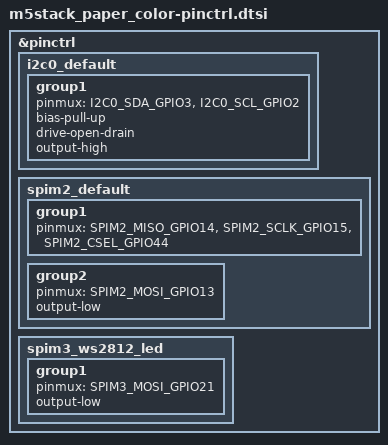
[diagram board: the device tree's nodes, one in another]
/*
 * Copyright (c) 2026 The Zephyr Project Contributors
 * SPDX-License-Identifier: Apache-2.0
 */

#include <zephyr/dt-bindings/pinctrl/esp32s3-pinctrl.h>

&pinctrl {
	i2c0_default: i2c0_default {
		group1 {
			pinmux = <I2C0_SDA_GPIO3>,
				 <I2C0_SCL_GPIO2>;
			bias-pull-up;
			drive-open-drain;
			output-high;
		};
	};

	spim2_default: spim2_default {
		group1 {
			pinmux = <SPIM2_MISO_GPIO14>,
				 <SPIM2_SCLK_GPIO15>,
				 <SPIM2_CSEL_GPIO44>;
		};

		group2 {
			pinmux = <SPIM2_MOSI_GPIO13>;
			output-low;
		};
	};

	spim3_ws2812_led: spim3_ws2812_led {
		group1 {
			pinmux = <SPIM3_MOSI_GPIO21>;
			output-low;
		};
	};
};
